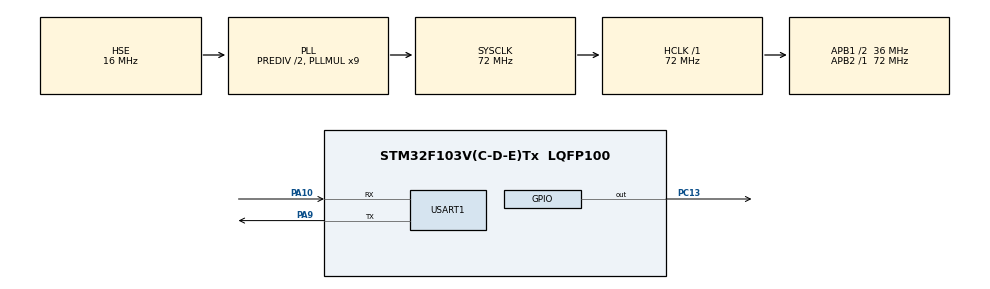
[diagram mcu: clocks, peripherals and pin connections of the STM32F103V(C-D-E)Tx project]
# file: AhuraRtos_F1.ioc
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Mcu.Family=STM32F1
Mcu.Name=STM32F103V(C-D-E)Tx
Mcu.Package=LQFP100
NVIC.PriorityGroup=NVIC_PRIORITYGROUP_4
NVIC.TIM2_IRQn=true\:15\:0\:false\:false\:true\:false\:true\:true
NVIC.TimeBase=TIM2_IRQn
NVIC.TimeBaseIP=TIM2
OSC_IN.Mode=HSE-External-Oscillator
OSC_IN.Signal=RCC_OSC_IN
OSC_OUT.Mode=HSE-External-Oscillator
OSC_OUT.Signal=RCC_OSC_OUT
PA10.Mode=Asynchronous
PA10.Signal=USART1_RX
PA13.Mode=Serial_Wire
PA13.Signal=SYS_JTMS-SWDIO
PA14.Mode=Serial_Wire
PA14.Signal=SYS_JTCK-SWCLK
PA9.Mode=Asynchronous
PA9.Signal=USART1_TX
PC13-TAMPER-RTC.Signal=GPIO_Output
ProjectManager.HeapSize=0x200
ProjectManager.StackSize=0x400
ProjectManager.TargetToolchain=STM32CubeIDE
RCC.AHBFreq_Value=72000000
RCC.APB1CLKDivider=RCC_HCLK_DIV2
RCC.APB1Freq_Value=36000000
RCC.APB1TimFreq_Value=72000000
RCC.APB2Freq_Value=72000000
RCC.APB2TimFreq_Value=72000000
RCC.HCLKFreq_Value=72000000
RCC.HSEDivPLL=RCC_HSE_PREDIV_DIV2
RCC.HSE_VALUE=16000000
RCC.PLLMUL=RCC_PLL_MUL9
RCC.PLLSourceVirtual=RCC_PLLSOURCE_HSE
RCC.SYSCLKFreq_VALUE=72000000
RCC.SYSCLKSource=RCC_SYSCLKSOURCE_PLLCLK
RCC.USBFreq_Value=72000000
USART1.VirtualMode=VM_ASYNC
VP_SYS_VS_tim2.Mode=TIM2
board=custom

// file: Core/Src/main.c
/* USER CODE BEGIN Header */
/**
  ******************************************************************************
  * @file           : main.c
  * @brief          : Main program body
  ******************************************************************************
  * @attention
  *
  * Copyright (c) 2026 STMicroelectronics.
  * All rights reserved.
  *
  * This software is licensed under terms that can be found in the LICENSE file
  * in the root directory of this software component.
  * If no LICENSE file comes with this software, it is provided AS-IS.
  *
  ******************************************************************************
  */
/* USER CODE END Header */
#include "main.h"

/* USER CODE BEGIN Includes */
#include "ahura.h"
/* USER CODE END Includes */

UART_HandleTypeDef huart1;

/* USER CODE BEGIN PV */
OS_TASK_DEFINE(led1_task, 512U);
OS_TASK_DEFINE(led2_task, 512U);
/* USER CODE END PV */

void SystemClock_Config(void);
static void MX_GPIO_Init(void);
static void MX_USART1_UART_Init(void);

/* USER CODE BEGIN 0 */
void os_main(void)
{
    /*while (1)
    {
        HAL_GPIO_TogglePin(GPIOC, GPIO_PIN_13);
        os_delay_ms(100);
        //os_delay_ms(500);
    }*/
}

void LED1_Task(void *arg)
{
	(void)arg;
    while (1)
    {
        HAL_GPIO_WritePin(GPIOC, GPIO_PIN_13,GPIO_PIN_SET);
        os_delay_ms(100);
    }
}

void LED2_Task(void *arg)
{
	(void)arg;
    while (1)
    {
    	HAL_GPIO_WritePin(GPIOC, GPIO_PIN_13,GPIO_PIN_RESET);
        os_delay_ms(200);
    }
}

int main(void)
{

  /* MCU Configuration--------------------------------------------------------*/

  /* Reset of all peripherals, Initializes the Flash interface and the Systick. */
  HAL_Init();

  /* Configure the system clock */
  SystemClock_Config();

  /* Initialize all configured peripherals */
  MX_GPIO_Init();
  MX_USART1_UART_Init();
  /* USER CODE BEGIN 2 */

  os_init();
  os_task_create(
      &led1_task,
      OS_TASK_CONFIG(LED1_Task, NULL, OS_TASK_PRIO_10)
  );

  os_task_create(
      &led2_task,
      OS_TASK_CONFIG(LED2_Task, NULL, OS_TASK_PRIO_5)
  );

  os_task_start(&led1_task);
  os_task_start(&led2_task);
  os_start();
  /* USER CODE END 2 */

  /* Infinite loop */
  /* USER CODE BEGIN WHILE */
  while (1)
  {
	  //HAL_GPIO_TogglePin(GPIOC, GPIO_PIN_13);
	  //HAL_Delay(500);
    /* USER CODE END WHILE */

  }
}

void SystemClock_Config(void)
{
  RCC_OscInitTypeDef RCC_OscInitStruct = {0};
  RCC_ClkInitTypeDef RCC_ClkInitStruct = {0};

  /** Initializes the RCC Oscillators according to the specified parameters
  * in the RCC_OscInitTypeDef structure.
  */
  RCC_OscInitStruct.OscillatorType = RCC_OSCILLATORTYPE_HSE;
  RCC_OscInitStruct.HSEState = RCC_HSE_ON;
  RCC_OscInitStruct.HSEPredivValue = RCC_HSE_PREDIV_DIV2;
  RCC_OscInitStruct.HSIState = RCC_HSI_ON;
  RCC_OscInitStruct.PLL.PLLState = RCC_PLL_ON;
  RCC_OscInitStruct.PLL.PLLSource = RCC_PLLSOURCE_HSE;
  RCC_OscInitStruct.PLL.PLLMUL = RCC_PLL_MUL9;
  if (HAL_RCC_OscConfig(&RCC_OscInitStruct) != HAL_OK)
  {
    Error_Handler();
  }

  /** Initializes the CPU, AHB and APB buses clocks
  */
  RCC_ClkInitStruct.ClockType = RCC_CLOCKTYPE_HCLK|RCC_CLOCKTYPE_SYSCLK
                              |RCC_CLOCKTYPE_PCLK1|RCC_CLOCKTYPE_PCLK2;
  RCC_ClkInitStruct.SYSCLKSource = RCC_SYSCLKSOURCE_PLLCLK;
  RCC_ClkInitStruct.AHBCLKDivider = RCC_SYSCLK_DIV1;
  RCC_ClkInitStruct.APB1CLKDivider = RCC_HCLK_DIV2;
  RCC_ClkInitStruct.APB2CLKDivider = RCC_HCLK_DIV1;

  if (HAL_RCC_ClockConfig(&RCC_ClkInitStruct, FLASH_LATENCY_2) != HAL_OK)
  {
    Error_Handler();
  }
}

static void MX_USART1_UART_Init(void)
{

  huart1.Instance = USART1;
  huart1.Init.BaudRate = 115200;
  huart1.Init.WordLength = UART_WORDLENGTH_8B;
  huart1.Init.StopBits = UART_STOPBITS_1;
  huart1.Init.Parity = UART_PARITY_NONE;
  huart1.Init.Mode = UART_MODE_TX_RX;
  huart1.Init.HwFlowCtl = UART_HWCONTROL_NONE;
  huart1.Init.OverSampling = UART_OVERSAMPLING_16;
  if (HAL_UART_Init(&huart1) != HAL_OK)
  {
    Error_Handler();
  }

}

static void MX_GPIO_Init(void)
{
  GPIO_InitTypeDef GPIO_InitStruct = {0};

  /* GPIO Ports Clock Enable */
  __HAL_RCC_GPIOC_CLK_ENABLE();
  __HAL_RCC_GPIOA_CLK_ENABLE();

  /*Configure GPIO pin Output Level */
  HAL_GPIO_WritePin(GPIOC, GPIO_PIN_13, GPIO_PIN_RESET);

  /*Configure GPIO pin : PC13 */
  GPIO_InitStruct.Pin = GPIO_PIN_13;
  GPIO_InitStruct.Mode = GPIO_MODE_OUTPUT_PP;
  GPIO_InitStruct.Pull = GPIO_NOPULL;
  GPIO_InitStruct.Speed = GPIO_SPEED_FREQ_LOW;
  HAL_GPIO_Init(GPIOC, &GPIO_InitStruct);

}

void HAL_TIM_PeriodElapsedCallback(TIM_HandleTypeDef *htim)
{
  if (htim->Instance == TIM2)
  {
    HAL_IncTick();
  }
}

void Error_Handler(void)
{
  __disable_irq();
  while (1)
  {
  }
}
